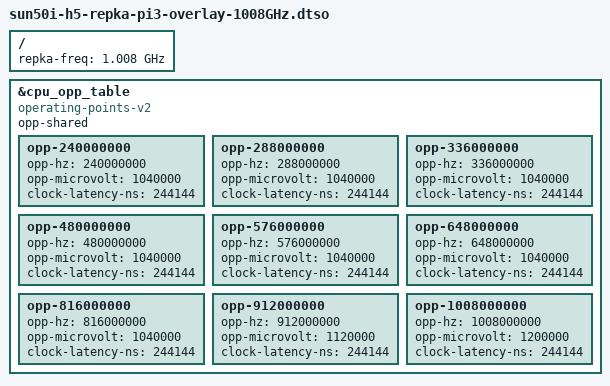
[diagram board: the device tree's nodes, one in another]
/dts-v1/;
/plugin/;

/ {
	fragment@0 {
		target-path = "/";
		__overlay__ {
			repka-freq = "1.008 GHz";
		};
	};

	fragment@1 {
		target = <&cpu_opp_table>;
		__overlay__ {
			compatible = "operating-points-v2";
			opp-shared;

			opp-240000000 {
				opp-hz = /bits/ 64 <240000000>;
				opp-microvolt = <1040000>;
				clock-latency-ns = <244144>; /* 8 32k periods */
			};

			opp-288000000 {
				opp-hz = /bits/ 64 <288000000>;
				opp-microvolt = <1040000>;
				clock-latency-ns = <244144>; /* 8 32k periods */
			};

			opp-336000000 {
				opp-hz = /bits/ 64 <336000000>;
				opp-microvolt = <1040000>;
				clock-latency-ns = <244144>; /* 8 32k periods */
			};

			opp-480000000 {
				opp-hz = /bits/ 64 <480000000>;
				opp-microvolt = <1040000>;
				clock-latency-ns = <244144>; /* 8 32k periods */
			};

			opp-576000000 {
				opp-hz = /bits/ 64 <576000000>;
				opp-microvolt = <1040000>;
				clock-latency-ns = <244144>; /* 8 32k periods */
			};

			opp-648000000 {
				opp-hz = /bits/ 64 <648000000>;
				opp-microvolt = <1040000>;
				clock-latency-ns = <244144>; /* 8 32k periods */
			};

			opp-816000000 {
				opp-hz = /bits/ 64 <816000000>;
				opp-microvolt = <1040000>;
				clock-latency-ns = <244144>; /* 8 32k periods */
			};

			opp-912000000 {
				opp-hz = /bits/ 64 <912000000>;
				opp-microvolt = <1120000>;
				clock-latency-ns = <244144>; /* 8 32k periods */
			};

			opp-1008000000 {
				opp-hz = /bits/ 64 <1008000000>;
				opp-microvolt = <1200000>;
				clock-latency-ns = <244144>; /* 8 32k periods */
			};
		};
	};
};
